VERSION ""

NS_ :

BS_:

BU_:
VAL_TABLE_ tab2 3 "Description for the value '0x3'" 2 "Description for the value '0x2'" 1 "Description for the value '0x1'" 0 "Description for the value '0x0'" ;
VAL_TABLE_ tab1 2 "Description for the value '0x2'" 1 "Description for the value '0x1'" 0 "Description for the value '0x0'" ;

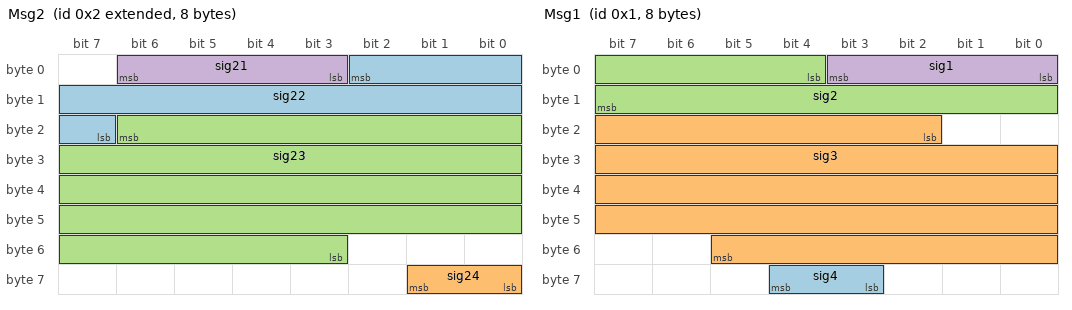
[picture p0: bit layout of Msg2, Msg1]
BO_ 2147483650 Msg2: 8 Vector__XXX
 SG_ sig22 : 2|12@0+ (1,0) [0|0] "" Vector__XXX
 SG_ sig24 : 57|2@0+ (1,0) [0|0] "" Vector__XXX
 SG_ sig23 : 22|36@0+ (1,0) [0|0] "" Vector__XXX
 SG_ sig21 : 6|4@0+ (1,0) [0|0] "" Vector__XXX

BO_ 1 Msg1: 8 Vector__XXX
 SG_ sig4 : 59|2@1+ (1,0) [0|0] "" Vector__XXX
 SG_ sig3 : 18|36@1+ (1,0) [0|0] "" Vector__XXX
 SG_ sig2 : 4|12@1+ (1,0) [0|0] "" Vector__XXX
 SG_ sig1 : 0|4@1+ (1,0) [0|0] "" Vector__XXX

BA_DEF_  "BusType" STRING ;
BA_DEF_DEF_  "BusType" "CAN";
VAL_ 1 sig4 2 "Description for the value '0x2'" 1 "Description for the value '0x1'" 0 "Description for the value '0x0'" ;
